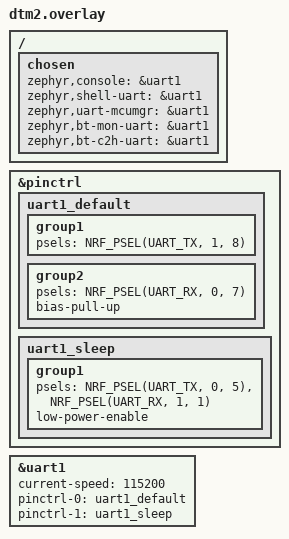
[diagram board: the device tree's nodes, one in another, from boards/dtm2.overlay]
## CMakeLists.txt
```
# SPDX-License-Identifier: Apache-2.0

cmake_minimum_required(VERSION 3.20.0)
find_package(Zephyr REQUIRED HINTS $ENV{ZEPHYR_BASE})
project(test_lora)

FILE(GLOB app_sources src/*.c)
target_sources(app PRIVATE ${app_sources})
target_include_directories(app PRIVATE 
    ${CMAKE_SOURCE_DIR}/../common/include
    )
```

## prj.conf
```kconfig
CONFIG_ZTEST=y
CONFIG_ZTEST_NEW_API=y

CONFIG_LORA_RAK3172=y

CONFIG_PCF85063A=n
CONFIG_COUNTER=n

# enable uart driver
CONFIG_SERIAL=y
# # Enable uart console
CONFIG_UART_CONSOLE=y
CONFIG_LOG=y

CONFIG_LORA=y
CONFIG_DOR_LORA=y
CONFIG_DOR_LORA_LOG_LEVEL_DBG=y
CONFIG_LORA_LOG_LEVEL_DBG=y

# Enable mcumgr.
CONFIG_MCUMGR=y
# Enable most core commands.
CONFIG_MCUMGR_GRP_IMG=y
```

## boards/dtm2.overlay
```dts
/ {
	chosen {
		zephyr,console = &uart1;
		zephyr,shell-uart = &uart1;
		zephyr,uart-mcumgr = &uart1;
		zephyr,bt-mon-uart = &uart1;
		zephyr,bt-c2h-uart = &uart1;
	};
};


/* tx_pin = 40, rx_pin = 7 */
&pinctrl {
    uart1_default: uart1_default {
        group1 {
            psels = <NRF_PSEL(UART_TX, 1, 8)>;
        };
        group2 {
            psels = <NRF_PSEL(UART_RX, 0, 7)>;
            bias-pull-up;
        };
    };
    uart1_sleep: uart1_sleep {
        group1 {
            psels = <NRF_PSEL(UART_TX, 0, 5)>,
                    <NRF_PSEL(UART_RX, 1, 1)>;
            low-power-enable;
        };
    };
};

&uart1 {
    status = "okay";
	current-speed = <115200>;
    pinctrl-0 = <&uart1_default>;
	pinctrl-1 = <&uart1_sleep>;
    pinctrl-names = "default", "sleep";
	/delete-property/ rtl8720cm;
};
```

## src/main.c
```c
#include <zephyr/ztest.h>
#include <zephyr/logging/log.h>
#include <zephyr/device.h>
#include <zephyr/drivers/lora.h>
#include <lorawan_module.h>

LOG_MODULE_REGISTER(lora_test);

#define DEFAULT_RADIO_NODE DT_ALIAS(lora0)
BUILD_ASSERT(DT_NODE_HAS_STATUS(DEFAULT_RADIO_NODE, okay),
	     "No default LoRa radio specified in DT");


struct dor_lora_tests_fixture {
	bool net_joined;
	const struct device *lora_module;
};

static struct dor_lora_tests_fixture test_fixture;

#define JOIN_TIMEOUT_SEC	(120)

static void *dor_lora_tests_setup(void)
{
	int retries = 0;
	struct mlorawan_join_config lorawan_join_config;
	lorawan_join_config.mode = LORAWAN_ACT_OTAA;
	lorawan_join_config.dev_class = LORAWAN_CLASS_A;

	test_fixture.lora_module = DEVICE_DT_GET(DEFAULT_RADIO_NODE);
	if(!test_fixture.lora_module )
		goto exit;
	while(retries < 5 && (mlorawan_join(test_fixture.lora_module, &lorawan_join_config)))
	{
		retries++;
	}
	if(retries < 5)
		test_fixture.net_joined = true;

exit:
	return &test_fixture;
}

ZTEST_SUITE(dor_lora_tests, NULL, dor_lora_tests_setup, NULL, NULL, NULL);

ZTEST_F(dor_lora_tests, test_simple_send)
{
	int ret;
	int fail_count = 0;
	uint8_t test_data[5] = {0xbb, 0xbb, 0xcc, 0xdd, 0xee};
	zassert_true(test_fixture.lora_module, "No lora module found");
	zassert_true(test_fixture.net_joined, "Failed to join network");
	for(int i = 0; i < 20; i++)
	{
		ret = mlorawan_send(test_fixture.lora_module, 1, test_data, 5, 1);
		if(ret)
			fail_count++;
	}
	zassert_true(fail_count == 20, "Failed to send %d times", fail_count);

}
```
